# LargeDummyDevice register map
File version: 1.0
Registers are 32-bit, read-write, no defined reset value unless marked. A register's access mark holds for its fields unless they carry their own. Offsets are from the block's base; [hi:lo] are bit positions.

## PERIPHERAL_13
Base 0x4000C000
0x04 REG_1 — Register 1
  [31:30] FIELD_16, [33:29] FIELD_11, [29:27] FIELD_8, [31:27] FIELD_13, [25] FIELD_9, [27:24] FIELD_14, [25:22] FIELD_5, [21] FIELD_17, [24:21] FIELD_22, [19] FIELD_6, [20:18] FIELD_18, [19:17] FIELD_19, [19:16] FIELD_10, [18:16] FIELD_21, [15] FIELD_7, [18:15] FIELD_20, [15:14] FIELD_3, [17:13] FIELD_1, [12:8] FIELD_15, [7:5] FIELD_23, [4] FIELD_2, [5:4] FIELD_4, [3:2] FIELD_12
0x08 REG_2 — Register 2
  [31] FIELD_11, [35:31] FIELD_29, [31:27] FIELD_22, [28:24] FIELD_7, [27:24] FIELD_28, [23:22] FIELD_4, [23:22] FIELD_24, [20:19] FIELD_27, [18] FIELD_1, [19:18] FIELD_23, [21:17] FIELD_21, [20:16] FIELD_13, [14:13] FIELD_6, [14:12] FIELD_25, [14:11] FIELD_9, [13:10] FIELD_8, [10] FIELD_14, [13:9] FIELD_5, [11:9] FIELD_15, [11:7] FIELD_10, [8:7] FIELD_12, [10:6] FIELD_16, [9:6] FIELD_20, [9:6] FIELD_26, [9:5] FIELD_2, [6:5] FIELD_17, [7:3] FIELD_18, [7:3] FIELD_19, [2:1] FIELD_3
0x0C REG_3 — Register 3
  [30:27] FIELD_5, [25:23] FIELD_6, [26:23] FIELD_7, [19:18] FIELD_3, [9:7] FIELD_2, [9:5] FIELD_4, [6:4] FIELD_1
0x10 REG_4 — Register 4
  [33:31] FIELD_12, [31:29] FIELD_2, [32:28] FIELD_1, [27] FIELD_11, [23:22] FIELD_9, [22:19] FIELD_8, [21:17] FIELD_6, [17:15] FIELD_7, [14:13] FIELD_14, [13:12] FIELD_13, [10:9] FIELD_5, [9:6] FIELD_3, [2:1] FIELD_4, [4:0] FIELD_10
0x14 REG_5 — Register 5
  [33:29] FIELD_4, [21:20] FIELD_2, [19] FIELD_3, [16] FIELD_5, [4] FIELD_1
0x18 REG_6 — Register 6
  [27:26] FIELD_4, [26:25] FIELD_3, [22:20] FIELD_7, [22:18] FIELD_2, [18:17] FIELD_1, [18:17] FIELD_5, [14:12] FIELD_9, [6:4] FIELD_6, [6:3] FIELD_8
0x1C REG_7 — Register 7
  [32:31] FIELD_13, [30:29] FIELD_22, [29:27] FIELD_7, [27] FIELD_9, [25] FIELD_20, [24:23] FIELD_5, [24:23] FIELD_6, [22] FIELD_8, [23:21] FIELD_1, [23:21] FIELD_12, [21:20] FIELD_3, [22:19] FIELD_10, [21:17] FIELD_17, [16:14] FIELD_14, [17:13] FIELD_18, [9] FIELD_4, [9:8] FIELD_21, [9:7] FIELD_11, [10:6] FIELD_19, [7:5] FIELD_23, [9:5] FIELD_24, [6:4] FIELD_15, [2] FIELD_2, [3:0] FIELD_16
0x20 REG_8 — Register 8
  [29:28] FIELD_14, [28] FIELD_15, [30:27] FIELD_13, [26:25] FIELD_12, [25:24] FIELD_1, [21] FIELD_3, [18:14] FIELD_8, [16:13] FIELD_4, [13] FIELD_5, [13:12] FIELD_9, [6] FIELD_6, [6:3] FIELD_7, [2:1] FIELD_2, [3:1] FIELD_16, [2:0] FIELD_10, [1:0] FIELD_11
0x24 REG_9 — Register 9
  [31] FIELD_10, [27] FIELD_7, [30:26] FIELD_6, [25:24] FIELD_3, [20] FIELD_12, [23:20] FIELD_18, [17] FIELD_11, [15] FIELD_8, [17:13] FIELD_2, [11] FIELD_1, [11:9] FIELD_5, [13:9] FIELD_16, [10:8] FIELD_4, [10:7] FIELD_13, [7:6] FIELD_9, [6:4] FIELD_17, [6:3] FIELD_14, [5:1] FIELD_15
0x28 REG_10 — Register 10
  [30:29] FIELD_14, [33:29] FIELD_25, [32:28] FIELD_21, [29:27] FIELD_11, [27] FIELD_12, [29:27] FIELD_13, [31:27] FIELD_20, [30:26] FIELD_15, [29:26] FIELD_22, [17:14] FIELD_10, [14:13] FIELD_4, [13] FIELD_8, [14:12] FIELD_6, [13:11] FIELD_24, [9:8] FIELD_9, [8] FIELD_16, [11:7] FIELD_5, [10:6] FIELD_2, [7:6] FIELD_19, [6] FIELD_23, [8:5] FIELD_7, [6:4] FIELD_18, [5:2] FIELD_1, [5:1] FIELD_3, [0] FIELD_17
0x2C REG_11 — Register 11
  [29:28] FIELD_1, [30:26] FIELD_3, [26] FIELD_5, [29:26] FIELD_6, [27:25] FIELD_12, [24] FIELD_13, [27:23] FIELD_4, [23] FIELD_8, [15] FIELD_2, [18:15] FIELD_17, [13:9] FIELD_7, [8:6] FIELD_9, [6] FIELD_11, [7:6] FIELD_16, [6:3] FIELD_15, [5:2] FIELD_14, [4:1] FIELD_10
0x30 REG_12 — Register 12
  [34:30] FIELD_4, [33:29] FIELD_6, [30:28] FIELD_12, [30:26] FIELD_1, [23] FIELD_10, [23:20] FIELD_9, [16:13] FIELD_7, [11] FIELD_3, [15:11] FIELD_5, [13:10] FIELD_2, [6:2] FIELD_11, [2:0] FIELD_8
0x34 REG_13 — Register 13
  [26:24] FIELD_10, [23:21] FIELD_5, [21:19] FIELD_7, [22:19] FIELD_11, [18:17] FIELD_1, [18:17] FIELD_3, [17:15] FIELD_8, [8] FIELD_4, [10:7] FIELD_6, [7:5] FIELD_9, [2:0] FIELD_2
0x38 REG_14 — Register 14
  [32:30] FIELD_2, [33:29] FIELD_4, [29:28] FIELD_8, [19:18] FIELD_5, [16:14] FIELD_7, [12:8] FIELD_6, [9:5] FIELD_3, [5:4] FIELD_1
0x3C REG_15 — Register 15
  [35:31] FIELD_16, [30] FIELD_4, [32:30] FIELD_18, [32:29] FIELD_3, [33:29] FIELD_6, [30:28] FIELD_27, [26] FIELD_12, [27:25] FIELD_13, [27:24] FIELD_9, [23:21] FIELD_17, [23:21] FIELD_24, [23:20] FIELD_19, [22:19] FIELD_14, [22:19] FIELD_15, [20:18] FIELD_7, [21:18] FIELD_8, [17] FIELD_21, [16:14] FIELD_29, [16:13] FIELD_23, [13:12] FIELD_1, [14:10] FIELD_20, [13:10] FIELD_28, [8] FIELD_22, [5] FIELD_26, [5:3] FIELD_2, [2] FIELD_5, [3:2] FIELD_11, [6:2] FIELD_25, [3:1] FIELD_10
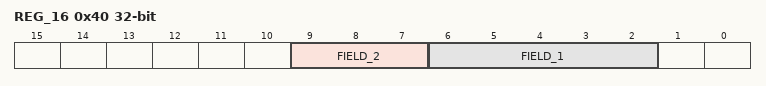
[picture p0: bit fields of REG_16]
0x40 REG_16 — Register 16
  [9:7] FIELD_2, [6:2] FIELD_1
